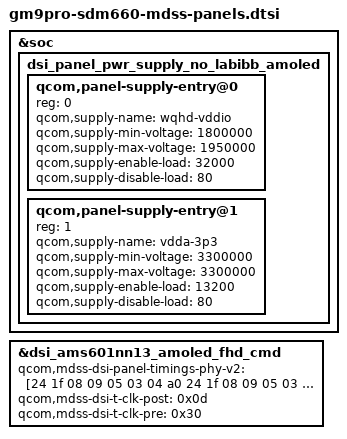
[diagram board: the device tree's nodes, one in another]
 /* SPDX-License-Identifier: GPL-2.0 */

#include "dsi-panel-ams601nn13-amoled-fhd-cmd.dtsi"

&soc {
	dsi_panel_pwr_supply_no_labibb_amoled: dsi_panel_pwr_supply_no_labibb_amoled {
		#address-cells = <1>;
		#size-cells = <0>;

		qcom,panel-supply-entry@0 {
			reg = <0>;
			qcom,supply-name = "wqhd-vddio";
			qcom,supply-min-voltage = <1800000>;
			qcom,supply-max-voltage = <1950000>;
			qcom,supply-enable-load = <32000>;
			qcom,supply-disable-load = <80>;
		};

		qcom,panel-supply-entry@1 {
			reg = <1>;
			qcom,supply-name = "vdda-3p3";
			qcom,supply-min-voltage = <3300000>;
			qcom,supply-max-voltage = <3300000>;
			qcom,supply-enable-load = <13200>;
			qcom,supply-disable-load = <80>;
		};
	};
};

&dsi_ams601nn13_amoled_fhd_cmd {
	qcom,mdss-dsi-panel-timings-phy-v2 = [24 1f 08 09 05 03 04 a0
		24 1f 08 09 05 03 04 a0
		24 1f 08 09 05 03 04 a0
		24 1f 08 09 05 03 04 a0
		24 1b 08 09 05 03 04 a0];
		qcom,mdss-dsi-t-clk-post = <0x0d>;
		qcom,mdss-dsi-t-clk-pre = <0x30>;
};
